VERSION ""

NS_ :

BS_:

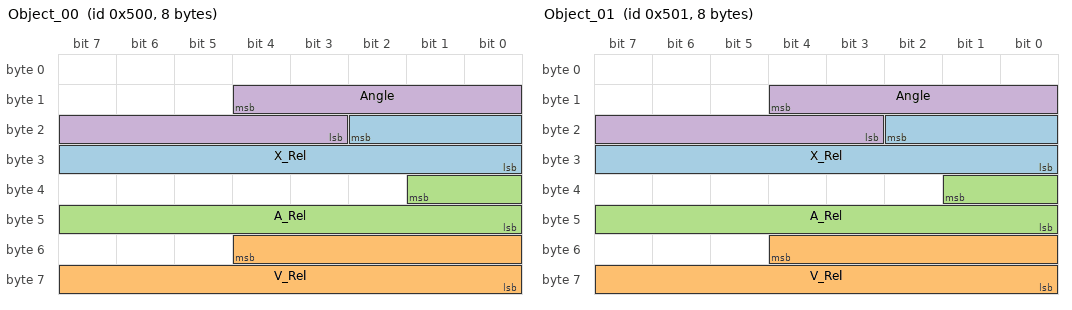
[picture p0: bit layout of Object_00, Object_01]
BO_ 1280 Object_00: 8 XXX
 SG_ X_Rel : 18|11@0+ (0.1,0) [0|0] "m" XXX
 SG_ V_Rel : 52|13@0- (0.01,0) [0|0] "m/s" XXX
 SG_ A_Rel : 33|10@0- (0.05,0) [0|0] "m/s2" XXX
 SG_ Angle : 12|10@0- (-0.1,0) [0|0] "deg" XXX

BO_ 1281 Object_01: 8 XXX
 SG_ X_Rel : 18|11@0+ (0.1,0) [0|0] "m" XXX
 SG_ V_Rel : 52|13@0- (0.01,0) [0|0] "m/s" XXX
 SG_ A_Rel : 33|10@0- (0.05,0) [0|0] "m/s2" XXX
 SG_ Angle : 12|10@0- (-0.1,0) [0|0] "deg" XXX

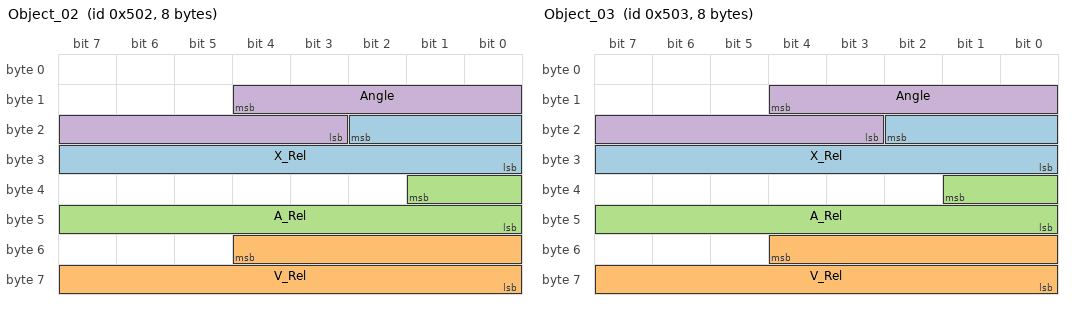
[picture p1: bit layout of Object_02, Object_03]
BO_ 1282 Object_02: 8 XXX
 SG_ X_Rel : 18|11@0+ (0.1,0) [0|0] "m" XXX
 SG_ V_Rel : 52|13@0- (0.01,0) [0|0] "m/s" XXX
 SG_ A_Rel : 33|10@0- (0.05,0) [0|0] "m/s2" XXX
 SG_ Angle : 12|10@0- (-0.1,0) [0|0] "deg" XXX

BO_ 1283 Object_03: 8 XXX
 SG_ X_Rel : 18|11@0+ (0.1,0) [0|0] "m" XXX
 SG_ V_Rel : 52|13@0- (0.01,0) [0|0] "m/s" XXX
 SG_ A_Rel : 33|10@0- (0.05,0) [0|0] "m/s2" XXX
 SG_ Angle : 12|10@0- (-0.1,0) [0|0] "deg" XXX

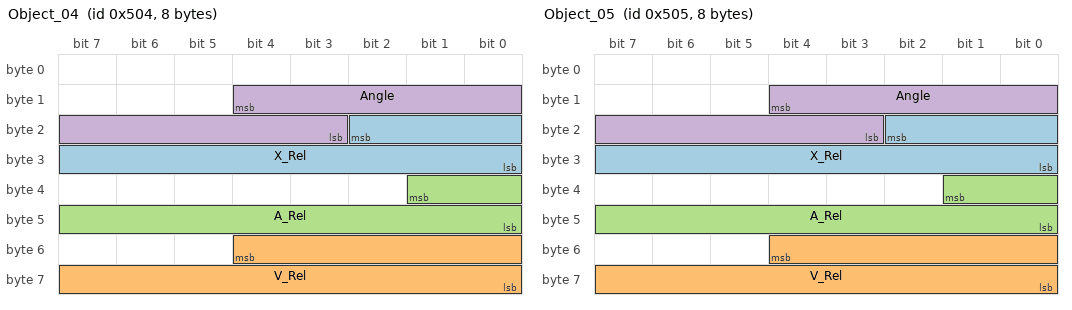
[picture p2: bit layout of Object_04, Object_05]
BO_ 1284 Object_04: 8 XXX
 SG_ X_Rel : 18|11@0+ (0.1,0) [0|0] "m" XXX
 SG_ V_Rel : 52|13@0- (0.01,0) [0|0] "m/s" XXX
 SG_ A_Rel : 33|10@0- (0.05,0) [0|0] "m/s2" XXX
 SG_ Angle : 12|10@0- (-0.1,0) [0|0] "deg" XXX

BO_ 1285 Object_05: 8 XXX
 SG_ X_Rel : 18|11@0+ (0.1,0) [0|0] "m" XXX
 SG_ V_Rel : 52|13@0- (0.01,0) [0|0] "m/s" XXX
 SG_ A_Rel : 33|10@0- (0.05,0) [0|0] "m/s2" XXX
 SG_ Angle : 12|10@0- (-0.1,0) [0|0] "deg" XXX

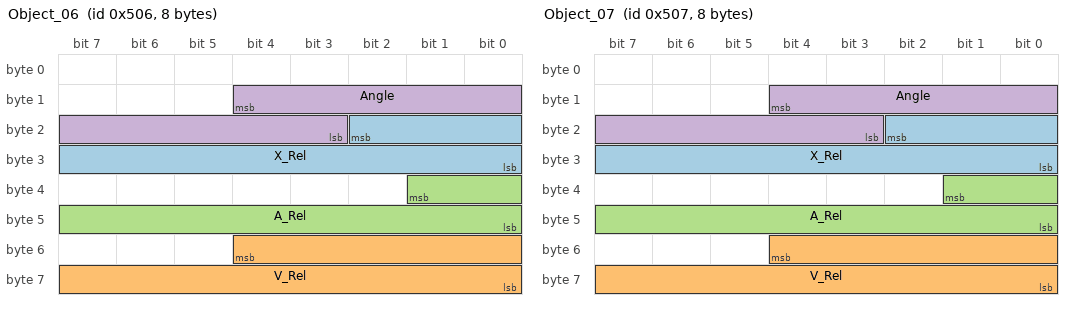
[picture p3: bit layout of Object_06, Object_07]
BO_ 1286 Object_06: 8 XXX
 SG_ X_Rel : 18|11@0+ (0.1,0) [0|0] "m" XXX
 SG_ V_Rel : 52|13@0- (0.01,0) [0|0] "m/s" XXX
 SG_ A_Rel : 33|10@0- (0.05,0) [0|0] "m/s2" XXX
 SG_ Angle : 12|10@0- (-0.1,0) [0|0] "deg" XXX

BO_ 1287 Object_07: 8 XXX
 SG_ X_Rel : 18|11@0+ (0.1,0) [0|0] "m" XXX
 SG_ V_Rel : 52|13@0- (0.01,0) [0|0] "m/s" XXX
 SG_ A_Rel : 33|10@0- (0.05,0) [0|0] "m/s2" XXX
 SG_ Angle : 12|10@0- (-0.1,0) [0|0] "deg" XXX

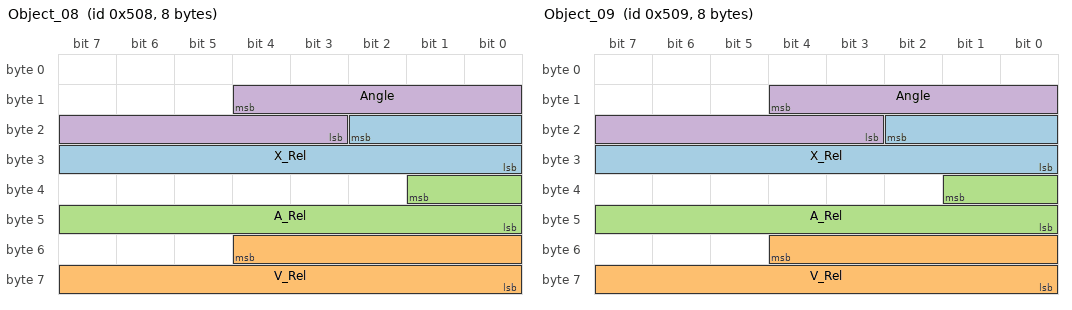
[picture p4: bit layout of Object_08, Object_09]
BO_ 1288 Object_08: 8 XXX
 SG_ X_Rel : 18|11@0+ (0.1,0) [0|0] "m" XXX
 SG_ V_Rel : 52|13@0- (0.01,0) [0|0] "m/s" XXX
 SG_ A_Rel : 33|10@0- (0.05,0) [0|0] "m/s2" XXX
 SG_ Angle : 12|10@0- (-0.1,0) [0|0] "deg" XXX

BO_ 1289 Object_09: 8 XXX
 SG_ X_Rel : 18|11@0+ (0.1,0) [0|0] "m" XXX
 SG_ V_Rel : 52|13@0- (0.01,0) [0|0] "m/s" XXX
 SG_ A_Rel : 33|10@0- (0.05,0) [0|0] "m/s2" XXX
 SG_ Angle : 12|10@0- (-0.1,0) [0|0] "deg" XXX

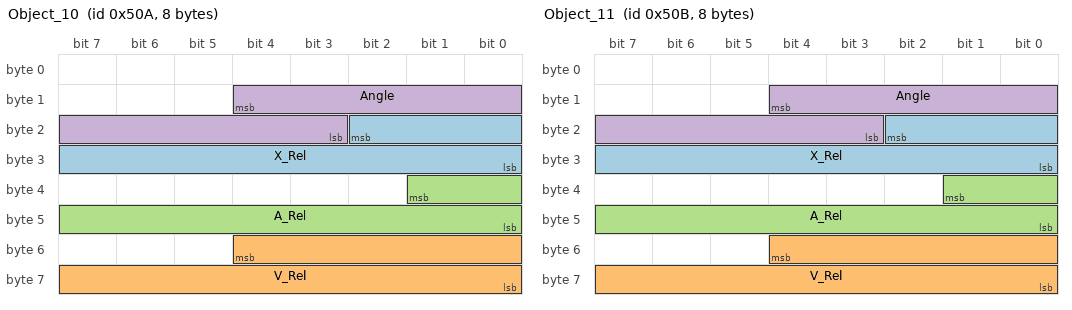
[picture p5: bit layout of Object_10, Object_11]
BO_ 1290 Object_10: 8 XXX
 SG_ X_Rel : 18|11@0+ (0.1,0) [0|0] "m" XXX
 SG_ V_Rel : 52|13@0- (0.01,0) [0|0] "m/s" XXX
 SG_ A_Rel : 33|10@0- (0.05,0) [0|0] "m/s2" XXX
 SG_ Angle : 12|10@0- (-0.1,0) [0|0] "deg" XXX

BO_ 1291 Object_11: 8 XXX
 SG_ X_Rel : 18|11@0+ (0.1,0) [0|0] "m" XXX
 SG_ V_Rel : 52|13@0- (0.01,0) [0|0] "m/s" XXX
 SG_ A_Rel : 33|10@0- (0.05,0) [0|0] "m/s2" XXX
 SG_ Angle : 12|10@0- (-0.1,0) [0|0] "deg" XXX

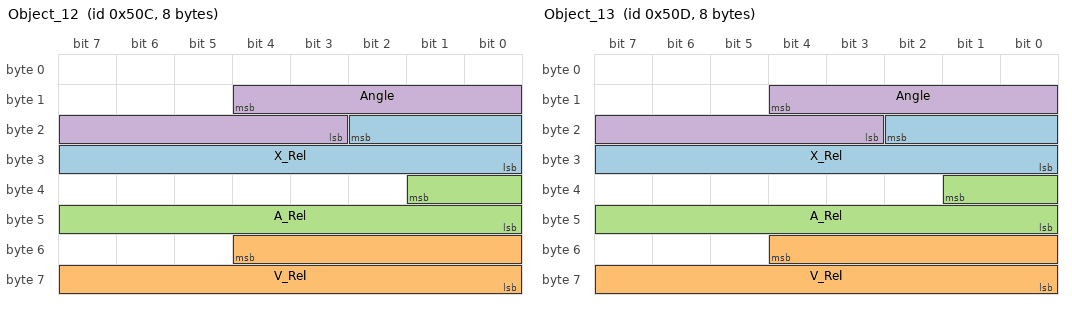
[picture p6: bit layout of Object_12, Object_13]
BO_ 1292 Object_12: 8 XXX
 SG_ X_Rel : 18|11@0+ (0.1,0) [0|0] "m" XXX
 SG_ V_Rel : 52|13@0- (0.01,0) [0|0] "m/s" XXX
 SG_ A_Rel : 33|10@0- (0.05,0) [0|0] "m/s2" XXX
 SG_ Angle : 12|10@0- (-0.1,0) [0|0] "deg" XXX

BO_ 1293 Object_13: 8 XXX
 SG_ X_Rel : 18|11@0+ (0.1,0) [0|0] "m" XXX
 SG_ V_Rel : 52|13@0- (0.01,0) [0|0] "m/s" XXX
 SG_ A_Rel : 33|10@0- (0.05,0) [0|0] "m/s2" XXX
 SG_ Angle : 12|10@0- (-0.1,0) [0|0] "deg" XXX

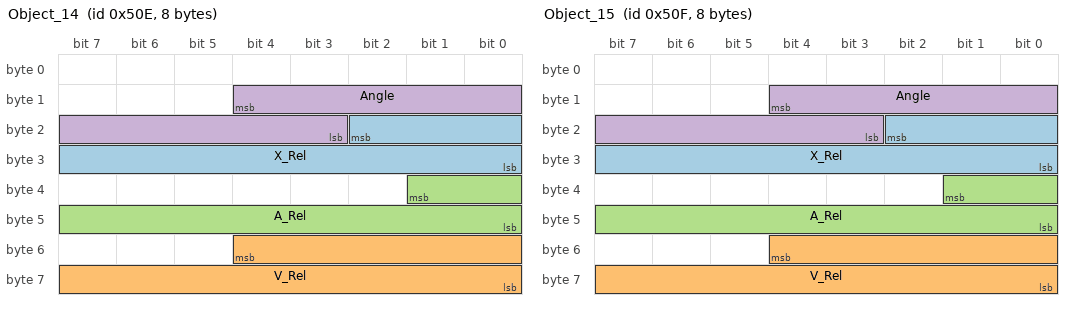
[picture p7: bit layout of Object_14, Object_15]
BO_ 1294 Object_14: 8 XXX
 SG_ X_Rel : 18|11@0+ (0.1,0) [0|0] "m" XXX
 SG_ V_Rel : 52|13@0- (0.01,0) [0|0] "m/s" XXX
 SG_ A_Rel : 33|10@0- (0.05,0) [0|0] "m/s2" XXX
 SG_ Angle : 12|10@0- (-0.1,0) [0|0] "deg" XXX

BO_ 1295 Object_15: 8 XXX
 SG_ X_Rel : 18|11@0+ (0.1,0) [0|0] "m" XXX
 SG_ V_Rel : 52|13@0- (0.01,0) [0|0] "m/s" XXX
 SG_ A_Rel : 33|10@0- (0.05,0) [0|0] "m/s2" XXX
 SG_ Angle : 12|10@0- (-0.1,0) [0|0] "deg" XXX

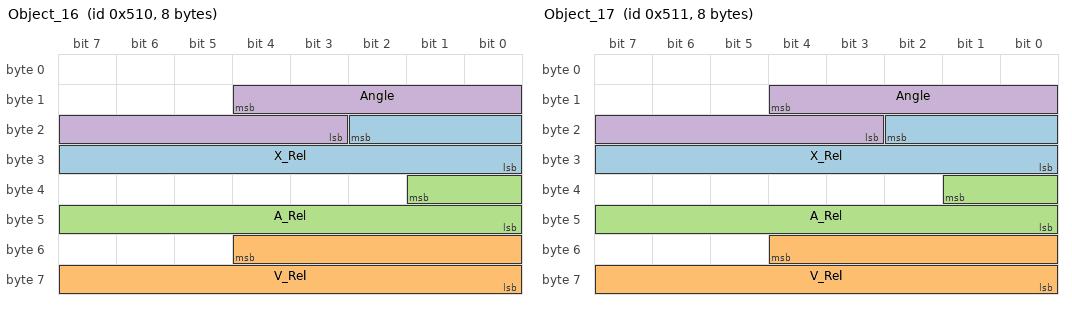
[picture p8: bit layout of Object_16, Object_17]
BO_ 1296 Object_16: 8 XXX
 SG_ X_Rel : 18|11@0+ (0.1,0) [0|0] "m" XXX
 SG_ V_Rel : 52|13@0- (0.01,0) [0|0] "m/s" XXX
 SG_ A_Rel : 33|10@0- (0.05,0) [0|0] "m/s2" XXX
 SG_ Angle : 12|10@0- (-0.1,0) [0|0] "deg" XXX

BO_ 1297 Object_17: 8 XXX
 SG_ X_Rel : 18|11@0+ (0.1,0) [0|0] "m" XXX
 SG_ V_Rel : 52|13@0- (0.01,0) [0|0] "m/s" XXX
 SG_ A_Rel : 33|10@0- (0.05,0) [0|0] "m/s2" XXX
 SG_ Angle : 12|10@0- (-0.1,0) [0|0] "deg" XXX

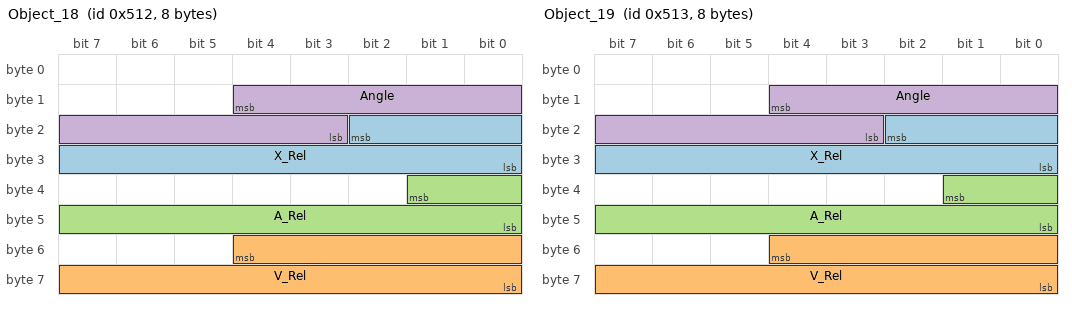
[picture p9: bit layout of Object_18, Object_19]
BO_ 1298 Object_18: 8 XXX
 SG_ X_Rel : 18|11@0+ (0.1,0) [0|0] "m" XXX
 SG_ V_Rel : 52|13@0- (0.01,0) [0|0] "m/s" XXX
 SG_ A_Rel : 33|10@0- (0.05,0) [0|0] "m/s2" XXX
 SG_ Angle : 12|10@0- (-0.1,0) [0|0] "deg" XXX

BO_ 1299 Object_19: 8 XXX
 SG_ X_Rel : 18|11@0+ (0.1,0) [0|0] "m" XXX
 SG_ V_Rel : 52|13@0- (0.01,0) [0|0] "m/s" XXX
 SG_ A_Rel : 33|10@0- (0.05,0) [0|0] "m/s2" XXX
 SG_ Angle : 12|10@0- (-0.1,0) [0|0] "deg" XXX

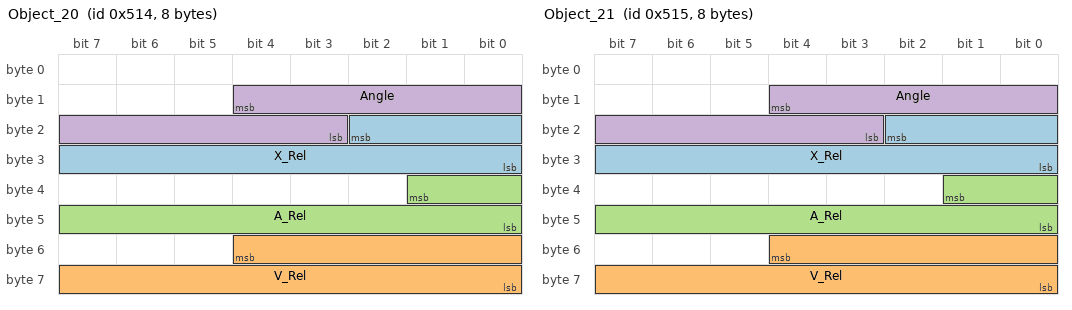
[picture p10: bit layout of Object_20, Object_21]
BO_ 1300 Object_20: 8 XXX
 SG_ X_Rel : 18|11@0+ (0.1,0) [0|0] "m" XXX
 SG_ V_Rel : 52|13@0- (0.01,0) [0|0] "m/s" XXX
 SG_ A_Rel : 33|10@0- (0.05,0) [0|0] "m/s2" XXX
 SG_ Angle : 12|10@0- (-0.1,0) [0|0] "deg" XXX

BO_ 1301 Object_21: 8 XXX
 SG_ X_Rel : 18|11@0+ (0.1,0) [0|0] "m" XXX
 SG_ V_Rel : 52|13@0- (0.01,0) [0|0] "m/s" XXX
 SG_ A_Rel : 33|10@0- (0.05,0) [0|0] "m/s2" XXX
 SG_ Angle : 12|10@0- (-0.1,0) [0|0] "deg" XXX

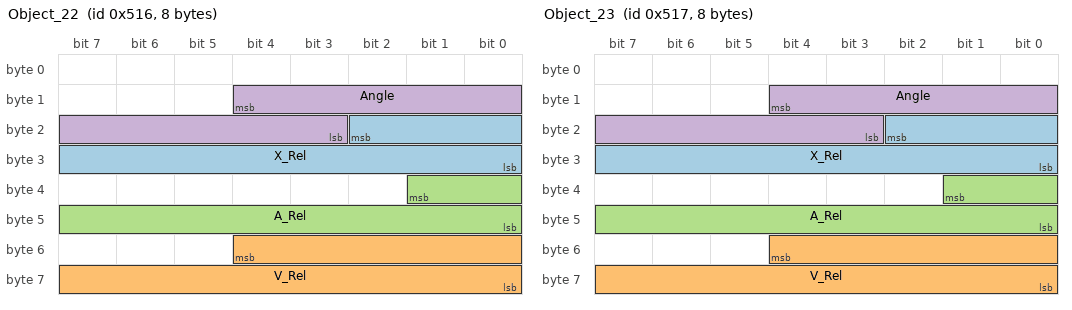
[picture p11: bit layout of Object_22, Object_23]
BO_ 1302 Object_22: 8 XXX
 SG_ X_Rel : 18|11@0+ (0.1,0) [0|0] "m" XXX
 SG_ V_Rel : 52|13@0- (0.01,0) [0|0] "m/s" XXX
 SG_ A_Rel : 33|10@0- (0.05,0) [0|0] "m/s2" XXX
 SG_ Angle : 12|10@0- (-0.1,0) [0|0] "deg" XXX

BO_ 1303 Object_23: 8 XXX
 SG_ X_Rel : 18|11@0+ (0.1,0) [0|0] "m" XXX
 SG_ V_Rel : 52|13@0- (0.01,0) [0|0] "m/s" XXX
 SG_ A_Rel : 33|10@0- (0.05,0) [0|0] "m/s2" XXX
 SG_ Angle : 12|10@0- (-0.1,0) [0|0] "deg" XXX

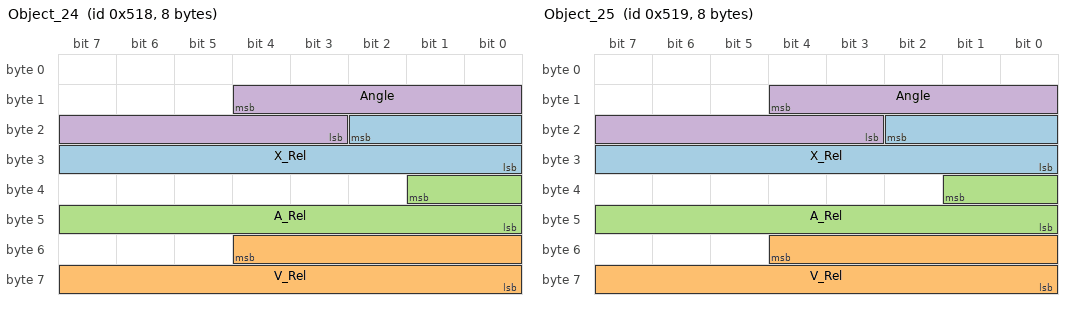
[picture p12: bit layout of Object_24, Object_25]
BO_ 1304 Object_24: 8 XXX
 SG_ X_Rel : 18|11@0+ (0.1,0) [0|0] "m" XXX
 SG_ V_Rel : 52|13@0- (0.01,0) [0|0] "m/s" XXX
 SG_ A_Rel : 33|10@0- (0.05,0) [0|0] "m/s2" XXX
 SG_ Angle : 12|10@0- (-0.1,0) [0|0] "deg" XXX

BO_ 1305 Object_25: 8 XXX
 SG_ X_Rel : 18|11@0+ (0.1,0) [0|0] "m" XXX
 SG_ V_Rel : 52|13@0- (0.01,0) [0|0] "m/s" XXX
 SG_ A_Rel : 33|10@0- (0.05,0) [0|0] "m/s2" XXX
 SG_ Angle : 12|10@0- (-0.1,0) [0|0] "deg" XXX

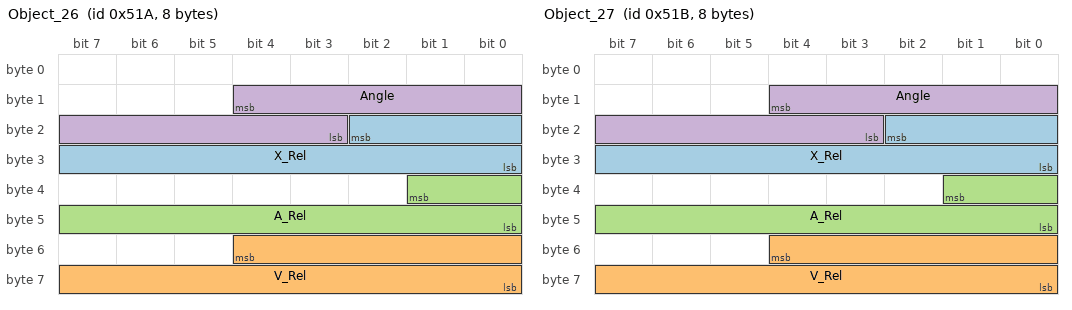
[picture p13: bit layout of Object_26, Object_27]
BO_ 1306 Object_26: 8 XXX
 SG_ X_Rel : 18|11@0+ (0.1,0) [0|0] "m" XXX
 SG_ V_Rel : 52|13@0- (0.01,0) [0|0] "m/s" XXX
 SG_ A_Rel : 33|10@0- (0.05,0) [0|0] "m/s2" XXX
 SG_ Angle : 12|10@0- (-0.1,0) [0|0] "deg" XXX

BO_ 1307 Object_27: 8 XXX
 SG_ X_Rel : 18|11@0+ (0.1,0) [0|0] "m" XXX
 SG_ V_Rel : 52|13@0- (0.01,0) [0|0] "m/s" XXX
 SG_ A_Rel : 33|10@0- (0.05,0) [0|0] "m/s2" XXX
 SG_ Angle : 12|10@0- (-0.1,0) [0|0] "deg" XXX

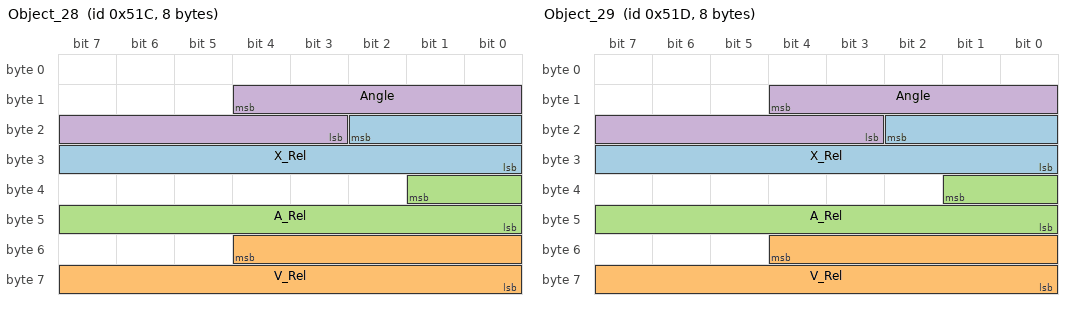
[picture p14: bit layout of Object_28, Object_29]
BO_ 1308 Object_28: 8 XXX
 SG_ X_Rel : 18|11@0+ (0.1,0) [0|0] "m" XXX
 SG_ V_Rel : 52|13@0- (0.01,0) [0|0] "m/s" XXX
 SG_ A_Rel : 33|10@0- (0.05,0) [0|0] "m/s2" XXX
 SG_ Angle : 12|10@0- (-0.1,0) [0|0] "deg" XXX

BO_ 1309 Object_29: 8 XXX
 SG_ X_Rel : 18|11@0+ (0.1,0) [0|0] "m" XXX
 SG_ V_Rel : 52|13@0- (0.01,0) [0|0] "m/s" XXX
 SG_ A_Rel : 33|10@0- (0.05,0) [0|0] "m/s2" XXX
 SG_ Angle : 12|10@0- (-0.1,0) [0|0] "deg" XXX

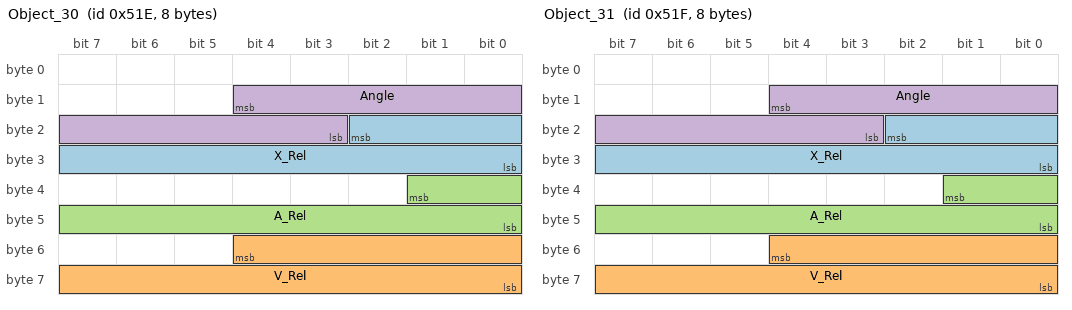
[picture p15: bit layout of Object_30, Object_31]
BO_ 1310 Object_30: 8 XXX
 SG_ X_Rel : 18|11@0+ (0.1,0) [0|0] "m" XXX
 SG_ V_Rel : 52|13@0- (0.01,0) [0|0] "m/s" XXX
 SG_ A_Rel : 33|10@0- (0.05,0) [0|0] "m/s2" XXX
 SG_ Angle : 12|10@0- (-0.1,0) [0|0] "deg" XXX

BO_ 1311 Object_31: 8 XXX
 SG_ X_Rel : 18|11@0+ (0.1,0) [0|0] "m" XXX
 SG_ V_Rel : 52|13@0- (0.01,0) [0|0] "m/s" XXX
 SG_ A_Rel : 33|10@0- (0.05,0) [0|0] "m/s2" XXX
 SG_ Angle : 12|10@0- (-0.1,0) [0|0] "deg" XXX

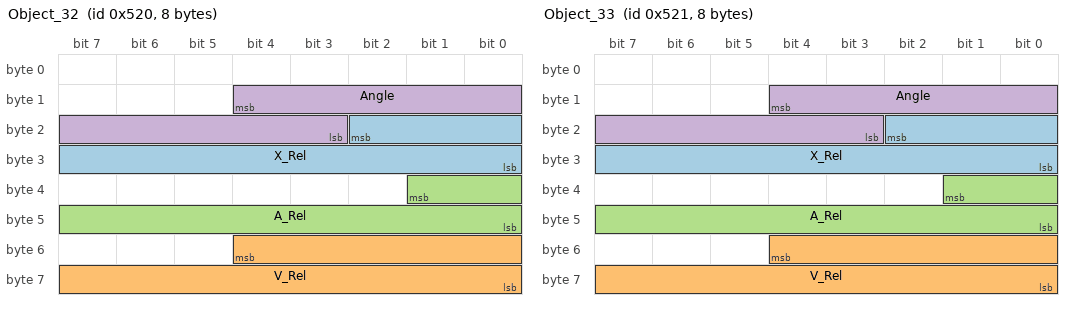
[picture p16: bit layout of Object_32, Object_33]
BO_ 1312 Object_32: 8 XXX
 SG_ X_Rel : 18|11@0+ (0.1,0) [0|0] "m" XXX
 SG_ V_Rel : 52|13@0- (0.01,0) [0|0] "m/s" XXX
 SG_ A_Rel : 33|10@0- (0.05,0) [0|0] "m/s2" XXX
 SG_ Angle : 12|10@0- (-0.1,0) [0|0] "deg" XXX

BO_ 1313 Object_33: 8 XXX
 SG_ X_Rel : 18|11@0+ (0.1,0) [0|0] "m" XXX
 SG_ V_Rel : 52|13@0- (0.01,0) [0|0] "m/s" XXX
 SG_ A_Rel : 33|10@0- (0.05,0) [0|0] "m/s2" XXX
 SG_ Angle : 12|10@0- (-0.1,0) [0|0] "deg" XXX

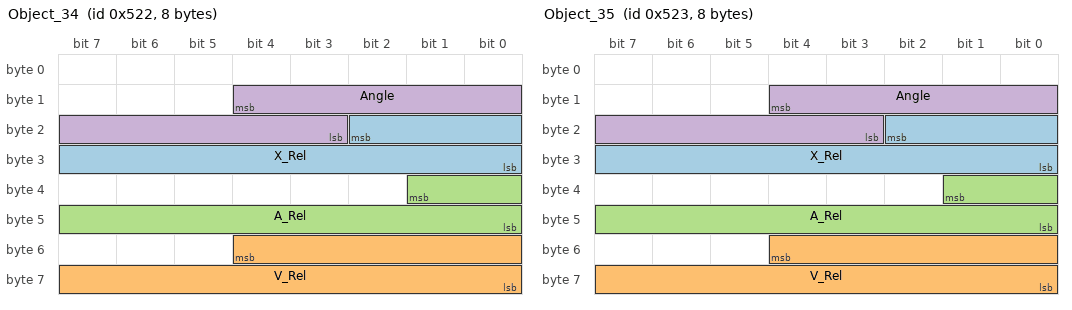
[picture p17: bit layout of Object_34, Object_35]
BO_ 1314 Object_34: 8 XXX
 SG_ X_Rel : 18|11@0+ (0.1,0) [0|0] "m" XXX
 SG_ V_Rel : 52|13@0- (0.01,0) [0|0] "m/s" XXX
 SG_ A_Rel : 33|10@0- (0.05,0) [0|0] "m/s2" XXX
 SG_ Angle : 12|10@0- (-0.1,0) [0|0] "deg" XXX

BO_ 1315 Object_35: 8 XXX
 SG_ X_Rel : 18|11@0+ (0.1,0) [0|0] "m" XXX
 SG_ V_Rel : 52|13@0- (0.01,0) [0|0] "m/s" XXX
 SG_ A_Rel : 33|10@0- (0.05,0) [0|0] "m/s2" XXX
 SG_ Angle : 12|10@0- (-0.1,0) [0|0] "deg" XXX

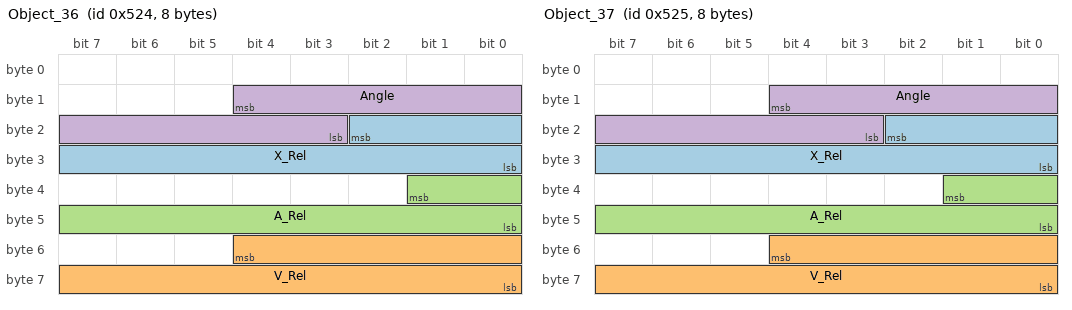
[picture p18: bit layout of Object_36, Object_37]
BO_ 1316 Object_36: 8 XXX
 SG_ X_Rel : 18|11@0+ (0.1,0) [0|0] "m" XXX
 SG_ V_Rel : 52|13@0- (0.01,0) [0|0] "m/s" XXX
 SG_ A_Rel : 33|10@0- (0.05,0) [0|0] "m/s2" XXX
 SG_ Angle : 12|10@0- (-0.1,0) [0|0] "deg" XXX

BO_ 1317 Object_37: 8 XXX
 SG_ X_Rel : 18|11@0+ (0.1,0) [0|0] "m" XXX
 SG_ V_Rel : 52|13@0- (0.01,0) [0|0] "m/s" XXX
 SG_ A_Rel : 33|10@0- (0.05,0) [0|0] "m/s2" XXX
 SG_ Angle : 12|10@0- (-0.1,0) [0|0] "deg" XXX

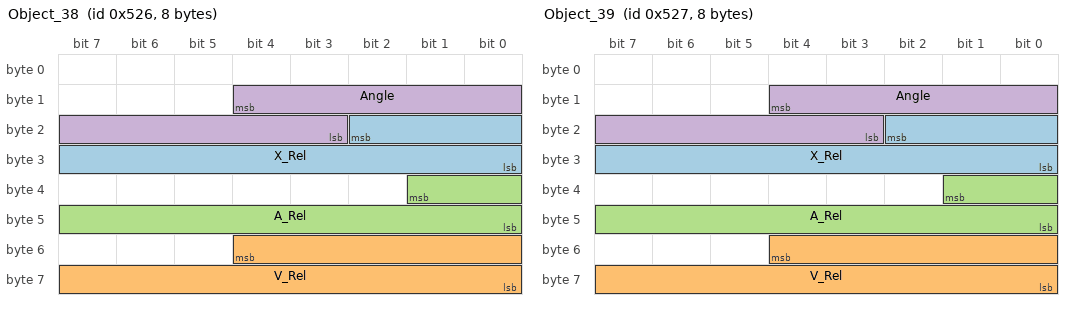
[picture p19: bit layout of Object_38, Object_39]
BO_ 1318 Object_38: 8 XXX
 SG_ X_Rel : 18|11@0+ (0.1,0) [0|0] "m" XXX
 SG_ V_Rel : 52|13@0- (0.01,0) [0|0] "m/s" XXX
 SG_ A_Rel : 33|10@0- (0.05,0) [0|0] "m/s2" XXX
 SG_ Angle : 12|10@0- (-0.1,0) [0|0] "deg" XXX

BO_ 1319 Object_39: 8 XXX
 SG_ X_Rel : 18|11@0+ (0.1,0) [0|0] "m" XXX
 SG_ V_Rel : 52|13@0- (0.01,0) [0|0] "m/s" XXX
 SG_ A_Rel : 33|10@0- (0.05,0) [0|0] "m/s2" XXX
 SG_ Angle : 12|10@0- (-0.1,0) [0|0] "deg" XXX

BO_ 1320 Object_40: 8 XXX
 SG_ X_Rel : 18|11@0+ (0.1,0) [0|0] "m" XXX
 SG_ V_Rel : 52|13@0- (0.01,0) [0|0] "m/s" XXX
 SG_ A_Rel : 33|10@0- (0.05,0) [0|0] "m/s2" XXX
 SG_ Angle : 12|10@0- (-0.1,0) [0|0] "deg" XXX

BO_ 1321 Object_41: 8 XXX
 SG_ X_Rel : 18|11@0+ (0.1,0) [0|0] "m" XXX
 SG_ V_Rel : 52|13@0- (0.01,0) [0|0] "m/s" XXX
 SG_ A_Rel : 33|10@0- (0.05,0) [0|0] "m/s2" XXX
 SG_ Angle : 12|10@0- (-0.1,0) [0|0] "deg" XXX

BO_ 1322 Object_42: 8 XXX
 SG_ X_Rel : 18|11@0+ (0.1,0) [0|0] "m" XXX
 SG_ V_Rel : 52|13@0- (0.01,0) [0|0] "m/s" XXX
 SG_ A_Rel : 33|10@0- (0.05,0) [0|0] "m/s2" XXX
 SG_ Angle : 12|10@0- (-0.1,0) [0|0] "deg" XXX

BO_ 1323 Object_43: 8 XXX
 SG_ X_Rel : 18|11@0+ (0.1,0) [0|0] "m" XXX
 SG_ V_Rel : 52|13@0- (0.01,0) [0|0] "m/s" XXX
 SG_ A_Rel : 33|10@0- (0.05,0) [0|0] "m/s2" XXX
 SG_ Angle : 12|10@0- (-0.1,0) [0|0] "deg" XXX

BO_ 1324 Object_44: 8 XXX
 SG_ X_Rel : 18|11@0+ (0.1,0) [0|0] "m" XXX
 SG_ V_Rel : 52|13@0- (0.01,0) [0|0] "m/s" XXX
 SG_ A_Rel : 33|10@0- (0.05,0) [0|0] "m/s2" XXX
 SG_ Angle : 12|10@0- (-0.1,0) [0|0] "deg" XXX

BO_ 1325 Object_45: 8 XXX
 SG_ X_Rel : 18|11@0+ (0.1,0) [0|0] "m" XXX
 SG_ V_Rel : 52|13@0- (0.01,0) [0|0] "m/s" XXX
 SG_ A_Rel : 33|10@0- (0.05,0) [0|0] "m/s2" XXX
 SG_ Angle : 12|10@0- (-0.1,0) [0|0] "deg" XXX

BO_ 1326 Object_46: 8 XXX
 SG_ X_Rel : 18|11@0+ (0.1,0) [0|0] "m" XXX
 SG_ V_Rel : 52|13@0- (0.01,0) [0|0] "m/s" XXX
 SG_ A_Rel : 33|10@0- (0.05,0) [0|0] "m/s2" XXX
 SG_ Angle : 12|10@0- (-0.1,0) [0|0] "deg" XXX

BO_ 1327 Object_47: 8 XXX
 SG_ X_Rel : 18|11@0+ (0.1,0) [0|0] "m" XXX
 SG_ V_Rel : 52|13@0- (0.01,0) [0|0] "m/s" XXX
 SG_ A_Rel : 33|10@0- (0.05,0) [0|0] "m/s2" XXX
 SG_ Angle : 12|10@0- (-0.1,0) [0|0] "deg" XXX

BO_ 1328 Object_48: 8 XXX
 SG_ X_Rel : 18|11@0+ (0.1,0) [0|0] "m" XXX
 SG_ V_Rel : 52|13@0- (0.01,0) [0|0] "m/s" XXX
 SG_ A_Rel : 33|10@0- (0.05,0) [0|0] "m/s2" XXX
 SG_ Angle : 12|10@0- (-0.1,0) [0|0] "deg" XXX

BO_ 1329 Object_49: 8 XXX
 SG_ X_Rel : 18|11@0+ (0.1,0) [0|0] "m" XXX
 SG_ V_Rel : 52|13@0- (0.01,0) [0|0] "m/s" XXX
 SG_ A_Rel : 33|10@0- (0.05,0) [0|0] "m/s2" XXX
 SG_ Angle : 12|10@0- (-0.1,0) [0|0] "deg" XXX

BO_ 1330 Object_50: 8 XXX
 SG_ X_Rel : 18|11@0+ (0.1,0) [0|0] "m" XXX
 SG_ V_Rel : 52|13@0- (0.01,0) [0|0] "m/s" XXX
 SG_ A_Rel : 33|10@0- (0.05,0) [0|0] "m/s2" XXX
 SG_ Angle : 12|10@0- (-0.1,0) [0|0] "deg" XXX

BO_ 1331 Object_51: 8 XXX
 SG_ X_Rel : 18|11@0+ (0.1,0) [0|0] "m" XXX
 SG_ V_Rel : 52|13@0- (0.01,0) [0|0] "m/s" XXX
 SG_ A_Rel : 33|10@0- (0.05,0) [0|0] "m/s2" XXX
 SG_ Angle : 12|10@0- (-0.1,0) [0|0] "deg" XXX

BO_ 1332 Object_52: 8 XXX
 SG_ X_Rel : 18|11@0+ (0.1,0) [0|0] "m" XXX
 SG_ V_Rel : 52|13@0- (0.01,0) [0|0] "m/s" XXX
 SG_ A_Rel : 33|10@0- (0.05,0) [0|0] "m/s2" XXX
 SG_ Angle : 12|10@0- (-0.1,0) [0|0] "deg" XXX

BO_ 1333 Object_53: 8 XXX
 SG_ X_Rel : 18|11@0+ (0.1,0) [0|0] "m" XXX
 SG_ V_Rel : 52|13@0- (0.01,0) [0|0] "m/s" XXX
 SG_ A_Rel : 33|10@0- (0.05,0) [0|0] "m/s2" XXX
 SG_ Angle : 12|10@0- (-0.1,0) [0|0] "deg" XXX

BO_ 1334 Object_54: 8 XXX
 SG_ X_Rel : 18|11@0+ (0.1,0) [0|0] "m" XXX
 SG_ V_Rel : 52|13@0- (0.01,0) [0|0] "m/s" XXX
 SG_ A_Rel : 33|10@0- (0.05,0) [0|0] "m/s2" XXX
 SG_ Angle : 12|10@0- (-0.1,0) [0|0] "deg" XXX

BO_ 1335 Object_55: 8 XXX
 SG_ X_Rel : 18|11@0+ (0.1,0) [0|0] "m" XXX
 SG_ V_Rel : 52|13@0- (0.01,0) [0|0] "m/s" XXX
 SG_ A_Rel : 33|10@0- (0.05,0) [0|0] "m/s2" XXX
 SG_ Angle : 12|10@0- (-0.1,0) [0|0] "deg" XXX

BO_ 1336 Object_56: 8 XXX
 SG_ X_Rel : 18|11@0+ (0.1,0) [0|0] "m" XXX
 SG_ V_Rel : 52|13@0- (0.01,0) [0|0] "m/s" XXX
 SG_ A_Rel : 33|10@0- (0.05,0) [0|0] "m/s2" XXX
 SG_ Angle : 12|10@0- (-0.1,0) [0|0] "deg" XXX

BO_ 1337 Object_57: 8 XXX
 SG_ X_Rel : 18|11@0+ (0.1,0) [0|0] "m" XXX
 SG_ V_Rel : 52|13@0- (0.01,0) [0|0] "m/s" XXX
 SG_ A_Rel : 33|10@0- (0.05,0) [0|0] "m/s2" XXX
 SG_ Angle : 12|10@0- (-0.1,0) [0|0] "deg" XXX

BO_ 1338 Object_58: 8 XXX
 SG_ X_Rel : 18|11@0+ (0.1,0) [0|0] "m" XXX
 SG_ V_Rel : 52|13@0- (0.01,0) [0|0] "m/s" XXX
 SG_ A_Rel : 33|10@0- (0.05,0) [0|0] "m/s2" XXX
 SG_ Angle : 12|10@0- (-0.1,0) [0|0] "deg" XXX

BO_ 1339 Object_59: 8 XXX
 SG_ X_Rel : 18|11@0+ (0.1,0) [0|0] "m" XXX
 SG_ V_Rel : 52|13@0- (0.01,0) [0|0] "m/s" XXX
 SG_ A_Rel : 33|10@0- (0.05,0) [0|0] "m/s2" XXX
 SG_ Angle : 12|10@0- (-0.1,0) [0|0] "deg" XXX

BO_ 1340 Object_60: 8 XXX
 SG_ X_Rel : 18|11@0+ (0.1,0) [0|0] "m" XXX
 SG_ V_Rel : 52|13@0- (0.01,0) [0|0] "m/s" XXX
 SG_ A_Rel : 33|10@0- (0.05,0) [0|0] "m/s2" XXX
 SG_ Angle : 12|10@0- (-0.1,0) [0|0] "deg" XXX

BO_ 1341 Object_61: 8 XXX
 SG_ X_Rel : 18|11@0+ (0.1,0) [0|0] "m" XXX
 SG_ V_Rel : 52|13@0- (0.01,0) [0|0] "m/s" XXX
 SG_ A_Rel : 33|10@0- (0.05,0) [0|0] "m/s2" XXX
 SG_ Angle : 12|10@0- (-0.1,0) [0|0] "deg" XXX

BO_ 1342 Object_62: 8 XXX
 SG_ X_Rel : 18|11@0+ (0.1,0) [0|0] "m" XXX
 SG_ V_Rel : 52|13@0- (0.01,0) [0|0] "m/s" XXX
 SG_ A_Rel : 33|10@0- (0.05,0) [0|0] "m/s2" XXX
 SG_ Angle : 12|10@0- (-0.1,0) [0|0] "deg" XXX

BU_: XXX

CM_ SG_ 357 GEAR "13P, 26R, 13N, 24D";
CM_ SG_ 605 PED_BRAKE "3: no brake, 4: brake";
CM_ SG_ 605 BRAKE_WARNING "Flashing brake warning and audible alert for potential forward collision";
CM_ SG_ 579 STEERING_ANGLE "steering angle aligns with 0.022 factor and -45.06 offset";
CM_ SG_ 863 SPEED_SIGN "speed limit in MPH";
CM_ SG_ 863 SPEED_SIGN_CAM "1: The speed limit is recognized by the camera. 0: speed limit is map based or is not available";
CM_ SG_ 863 STOP_SIGN "value 9 when stop sign is active";
CM_ SG_ 1157 SBS_WARNING_DISTANCE "1 far, 2 mid, 3 near";
CM_ SG_ 1157 SBS_SCBC "1 off, 2 on";
CM_ SG_ 1157 LKAS_ASSIT_TIMING "1 at, 0 before";
CM_ SG_ 1157 LKAS_SENSETIVITY "0 low, 1 high";
CM_ SG_ 1157 LANEE_DEPARTURE_ALERT "1 off, 2 on";
CM_ SG_ 1157 WARNING "1 Rare, 0 often";
CM_ SG_ 1088 LANE_LINES "0 LKAS disabled, 1 no lines, 2 two lines, 3 left line, 4 right line";
CM_ SG_ 1088 TJA "2: crz not active,  3: TJA not allowed,  4: TJA allowed";
CM_ SG_ 1088 TJA_TRANSITION "3: if TJA signal is 3, otherwise set to 0";
CM_ SG_ 1045 ABS_MALFUNCTION "off: 0, solid: 1, slow blink: 2, fast blink: 3";
CM_ SG_ 120 VEHICLE_ACC_X "Vehicle acceleration of X-axis wrt. NED frame.";
CM_ SG_ 120 VEHICLE_ACC_Y "Vehicle acceleration of Y-axis wrt. NED frame.";
CM_ SG_ 157 CAN_OFF "Disengage Cruise if enabled, if already disabled  TURN it OFF ";
CM_ SG_ 552 GEAR "0 Shifting, 1 P, 2 R, 3 N, 4 D";
CM_ SG_ 552 GEAR_BOX "0 P, 14 R, 1 though 6 D for speeds, 15 Shift";
CM_ SG_ 540 HANDS_ON_STEER_WARN "0 no warning, b warning";
CM_ SG_ 540 DISTANCE_SETTING "Radar distance 0: disabled, 1: 4 bars, 2: 3 bars, 3: 2 bars, 4: 1 bar";
CM_ SG_ 1143 REAR_CT_ALERT "Rear Cross Traffic Alert";
VAL_ 780 CRUISE_SPEED 255 "no_speed" 252 "stopped";
VAL_ 780 HUD_LEAD 3 "acc_off" 2 "solid_car" 1 "dashed_car" 0 "no_car";
VAL_ 884 DASHBOARD_ALERT 0 "none" 51 "acc_problem" 55 "cmbs_problem" 75 "key_not_detected" 79 "fasten_seatbelt" 111 "lkas_problem" 131 "brake_system_problem" 132 "brake_hold_problem" 139 "tbd" 161 "door_open";
VAL_ 891 WIPERS 4 "High" 2 "Low" 0 "Off";

VAL_ 399 STEER_STATUS 6 "tmp_fault" 5 "fault_1" 4 "no_torque_alert_2" 3 "low_speed_lockout" 2 "no_torque_alert_1" 0 "normal";

VAL_ 829 BEEP 3 "single_beep" 2 "triple_beep" 1 "repeated_beep" 0 "no_beep";

VAL_ 401 GEAR_SHIFTER 32 "L" 16 "S" 8 "D" 4 "N" 2 "R" 1 "P" ;
VAL_ 401 GEAR 7 "L" 10 "S" 4 "D" 3 "N" 2 "R" 1 "P" ;
VAL_ 545 ECON_ON_2 0 "off" 3 "on" ;
VAL_ 662 CRUISE_BUTTONS 7 "tbd" 6 "tbd" 5 "tbd" 4 "accel_res" 3 "decel_set" 2 "cancel" 1 "main" 0 "none" ;
VAL_ 662 CRUISE_SETTING 3 "distance_adj" 2 "tbd" 1 "lkas_button" 0 "none" ;
